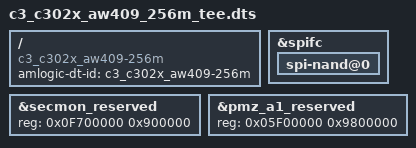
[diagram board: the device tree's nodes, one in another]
// SPDX-License-Identifier: (GPL-2.0+ OR MIT)
/*
 * Copyright (c) 2019 Amlogic, Inc. All rights reserved.
 */

/dts-v1/;

#include "c3_c30xx_aw409_256m.dtsi"
/ {
	amlogic-dt-id = "c3_c302x_aw409-256m";
	compatible = "c3_c302x_aw409-256m";
};

&spifc {
	spi-nand@0 {
		status = "okay";
	};
};

&secmon_reserved {
	reg = <0x0F700000 0x900000>;
};

&pmz_a1_reserved {
	reg = <0x05F00000 0x9800000>;
};
